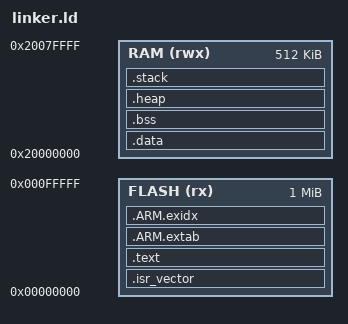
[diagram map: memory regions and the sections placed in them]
/*
 * linker.ld — nRF5340 application-core memory map and linker script.
 *
 * Author: jayis1
 * Copyright (C) 2026 jayis1. All rights reserved.
 * License: GPL-3.0
 */

MEMORY
{
    FLASH (rx) : ORIGIN = 0x00000000, LENGTH = 1024K
    RAM   (rwx) : ORIGIN = 0x20000000, LENGTH = 512K
}

ENTRY(Reset_Handler)

SECTIONS
{
    .isr_vector :
    {
        . = ALIGN(4);
        KEEP(*(.isr_vector))
        . = ALIGN(4);
    } > FLASH

    .text :
    {
        . = ALIGN(4);
        *(.text)
        *(.text*)
        *(.rodata)
        *(.rodata*)
        . = ALIGN(4);
        _etext = .;
    } > FLASH

    .ARM.extab :
    {
        *(.ARM.extab* .gnu.linkonce.armextab.*)
    } > FLASH

    .ARM.exidx :
    {
        __exidx_start = .;
        *(.ARM.exidx* .gnu.linkonce.armexidx.*)
        __exidx_end = .;
    } > FLASH

    .data : AT (_etext)
    {
        . = ALIGN(4);
        _sdata = .;
        *(.data)
        *(.data*)
        . = ALIGN(4);
        _edata = .;
    } > RAM

    .bss (NOLOAD) :
    {
        . = ALIGN(4);
        _sbss = .;
        *(.bss)
        *(.bss*)
        *(COMMON)
        . = ALIGN(4);
        _ebss = .;
    } > RAM

    .heap (NOLOAD) :
    {
        . = ALIGN(8);
        _sheap = .;
        . = . + 0x4000;   /* 16 KB heap */
        _eheap = .;
    } > RAM

    .stack (NOLOAD) :
    {
        . = ALIGN(8);
        _sstack = .;
        . = . + 0x2000;   /* 8 KB stack */
        _estack = .;
    } > RAM

    _end = .;
    end = .;
}

PROVIDE(_estack_top = ORIGIN(RAM) + LENGTH(RAM));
